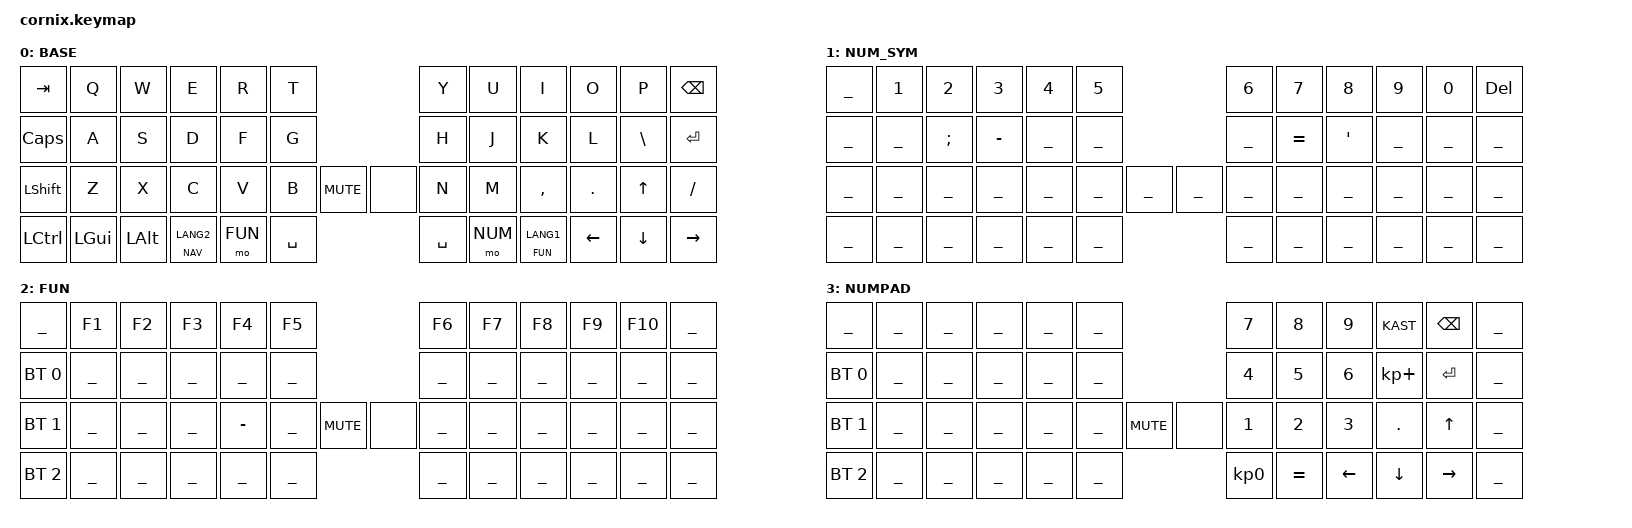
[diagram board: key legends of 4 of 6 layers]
/* ここまでは元コードと同じ */

#define BASE 0
#define NAV 1      // ここを「数字・記号レイヤ」として使う
#define NUM 2      // テンキー
#define FUN 3      // F1〜F10
#define SYM 4
#define MOUSE 5

/* …中略… */

 / {
   keymap {
      compatible = "zmk,keymap";

      /* Layer 0: BASE  ─ スクショの通常レイヤ */
      default_layer {
         display-name = "BASE";
         bindings = <
// ╭──────────────┬──────────────┬──────────────┬──────────────┬──────────────┬──────────────╮                               ╭──────────────┬──────────────┬──────────────┬──────────────┬────────────────┬──────────────╮
     &kp TAB        &kp Q          &kp W          &kp E          &kp R          &kp T                                          &kp Y          &kp U          &kp I          &kp O          &kp P            &kp BKSP
// ├──────────────┼──────────────┼──────────────┼──────────────┼──────────────┼──────────────┤                               ├──────────────┼──────────────┼──────────────┼──────────────┼────────────────┼──────────────┤
     &kp CAPSLOCK   &kp A          &kp S          &kp D          &kp F          &kp G                                          &kp H          &kp J          &kp K          &kp L          &kp BSLH         &kp ENTER
// ├──────────────┼──────────────┼──────────────┼──────────────┼──────────────┼──────────────┤──────────────╮ ╭──────────────├──────────────┼──────────────┼──────────────┼──────────────┼────────────────┼──────────────┤
     &kp LSHFT      &kp Z          &kp X          &kp C          &kp V          &kp B          &kp C_MUTE       &none          &kp N          &kp M          &kp COMMA      &kp DOT        &kp UP           &kp SLASH
// ╰──────────────┴──────────────┴──────────────┴──────────────┼──────────────┼──────────────┤──────────────╯ ╰──────────────├──────────────┼──────────────┼──────────────┼──────────────┼────────────────┼──────────────╯
     &kp LCTRL      &kp LGUI       &kp LALT       &lt NAV LANG2    &mo FUN        &kp SPACE                                      &kp SPACE      &mo NUM        &lt FUN LANG1   &kp LEFT       &kp DOWN         &kp RIGHT
// ╰──────────────┴──────────────┴──────────────┴──────────────┴──────────────┴──────────────╯                               ╰──────────────┴──────────────┴──────────────┴──────────────┴────────────────┴──────────────╯ 
         >;
         sensor-bindings = <&inc_dec_kp C_VOL_UP C_VOL_DN &inc_dec_kp PG_DN PG_UP>;
      };

      /* Layer 1: NAV → 数字・記号レイヤ（Esc, 1〜0, ; - = '） */
      nav_layer {
         display-name = "NUM_SYM";
         bindings = <
// ╭──────────────┬──────────────┬──────────────┬──────────────┬──────────────┬──────────────╮                               ╭──────────────┬──────────────┬──────────────┬──────────────┬──────────────┬──────────────╮
     ___            &kp N1         &kp N2         &kp N3         &kp N4         &kp N5                                         &kp N6         &kp N7         &kp N8         &kp N9         &kp N0         &kp DEL
// ├──────────────┼──────────────┼──────────────┼──────────────┼──────────────┼──────────────┤                               ├──────────────┼──────────────┼──────────────┼──────────────┼──────────────┼──────────────┤
     ___            ___            &kp SEMI       &kp MINUS      ___            ___                                            ___            &kp EQUAL      &kp SQT        ___            ___            ___
// ├──────────────┼──────────────┼──────────────┼──────────────┼──────────────┼──────────────┤──────────────╮ ╭──────────────├──────────────┼──────────────┼──────────────┼──────────────┼──────────────┼──────────────┤
     ___            ___            ___            ___            ___            ___            ___              ___            ___            ___            ___            ___            ___            ___   
// ╰──────────────┴──────────────┴──────────────┴──────────────┼──────────────┼──────────────┤──────────────╯ ╰──────────────├──────────────┼──────────────┼──────────────┼──────────────┼──────────────┼──────────────╯
     ___            ___            ___            ___            ___            ___                                            ___            ___            ___            ___            ___            ___
// ╰──────────────┴──────────────┴──────────────┴──────────────┴──────────────┴──────────────╯                               ╰──────────────┴──────────────┴──────────────┴──────────────┴──────────────┴──────────────╯
         >;
      };

      /* Layer 2: NUM → F1〜F10＋BT0/1/2 */
      numbers_layer {
         display-name = "FUN";
         bindings = <
// ╭──────────────┬──────────────┬──────────────┬──────────────┬──────────────┬──────────────╮                               ╭──────────────┬──────────────┬──────────────┬──────────────┬──────────────┬──────────────╮
     ___            &kp F1         &kp F2         &kp F3         &kp F4         &kp F5                                         &kp F6         &kp F7         &kp F8         &kp F9         &kp F10        ___   
// ├──────────────┼──────────────┼──────────────┼──────────────┼──────────────┼──────────────┤                               ├──────────────┼──────────────┼──────────────┼──────────────┼──────────────┼──────────────┤
     &bt BT_SEL 0   ___            ___            ___            ___            ___                                            ___            ___            ___            ___            ___            ___   
// ├──────────────┼──────────────┼──────────────┼──────────────┼──────────────┼──────────────┤──────────────╮ ╭──────────────├──────────────┼──────────────┼──────────────┼──────────────┼──────────────┼──────────────┤
     &bt BT_SEL 1   ___            ___            ___            &kp MINUS      ___            &kp C_MUTE       &none          ___            ___            ___            ___            ___            ___   
// ╰──────────────┴──────────────┴──────────────┴──────────────┼──────────────┼──────────────┤──────────────╯ ╰──────────────├──────────────┼──────────────┼──────────────┼──────────────┼──────────────┼──────────────╯
     &bt BT_SEL 2   ___            ___            ___            ___            ___                                            ___            ___            ___            ___            ___            ___
// ╰──────────────┴──────────────┴──────────────┴──────────────┴──────────────┴──────────────╯                               ╰──────────────┴──────────────┴──────────────┴──────────────┴──────────────┴──────────────╯
         >;
      };

      /* Layer 3: FUN → テンキー（7〜0, *, +, =, Bksp, Enter, 矢印） */
      function_layer {
         display-name = "NUMPAD";
         bindings = <
// ╭──────────────┬──────────────┬──────────────┬──────────────┬──────────────┬──────────────╮                               ╭──────────────┬──────────────┬──────────────┬──────────────┬──────────────┬──────────────╮
     ___            ___            ___            ___            ___            ___                                            &kp N7         &kp N8         &kp N9         &kp KAST       &kp BKSP       ___   
// ├──────────────┼──────────────┼──────────────┼──────────────┼──────────────┼──────────────┤                               ├──────────────┼──────────────┼──────────────┼──────────────┼──────────────┼──────────────┤
     &bt BT_SEL 0   ___            ___            ___            ___            ___                                            &kp N4         &kp N5         &kp N6         &kp KP_PLUS    &kp ENTER      ___   
// ├──────────────┼──────────────┼──────────────┼──────────────┼──────────────┼──────────────┤──────────────╮ ╭──────────────├──────────────┼──────────────┼──────────────┼──────────────┼──────────────┼──────────────┤
     &bt BT_SEL 1   ___            ___            ___            ___            ___            &kp C_MUTE       &none          &kp N1         &kp N2         &kp N3         &kp DOT        &kp UP         ___   
// ╰──────────────┴──────────────┴──────────────┴──────────────┼──────────────┼──────────────┤──────────────╯ ╰──────────────├──────────────┼──────────────┼──────────────┼──────────────┼──────────────┼──────────────╯
     &bt BT_SEL 2   ___            ___            ___            ___            ___                                            &kp KP_N0      &kp EQUAL      &kp LEFT       &kp DOWN       &kp RIGHT      ___
// ╰──────────────┴──────────────┴──────────────┴──────────────┴──────────────┴──────────────╯                               ╰──────────────┴──────────────┴──────────────┴──────────────┴──────────────┴──────────────╯
         >;
      };

      /* Layer 4, 5: もともとの SYM / MOUSE はそのまま */
      symbols_layer {
         display-name = "SYM";
         bindings = <
           /* 元の定義そのまま */
           // ...
         >;
      };

      mouse_layer {
         display-name = "MOUSE";
         bindings = <
           /* 元の定義そのまま */
           // ...
         >;
      };

   }; // END keymap
}; // END
